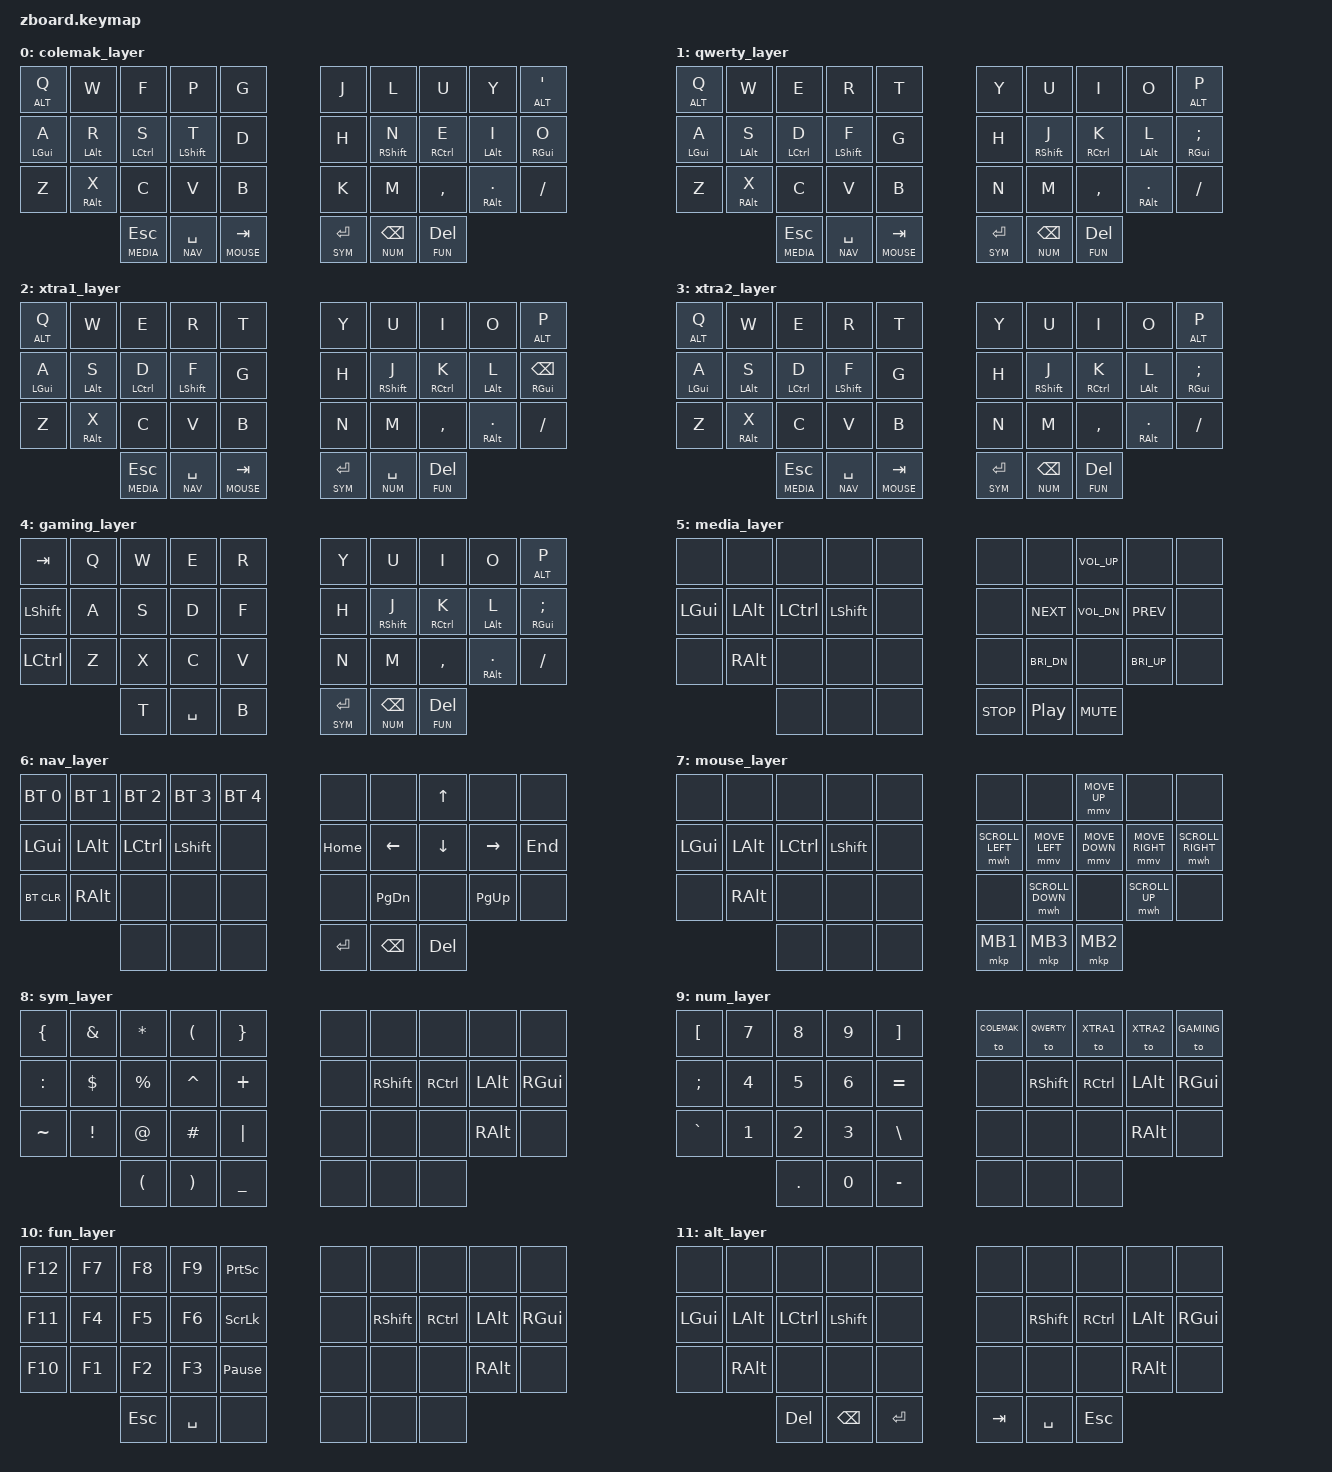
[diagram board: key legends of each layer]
/*
 * Copyright (c) 2020 The ZMK Contributors
 *
 * SPDX-License-Identifier: MIT
 */

#include <behaviors.dtsi>
#include <dt-bindings/zmk/keys.h>
#include <dt-bindings/zmk/bt.h>
#include <dt-bindings/zmk/mouse.h>


&mt {
   flavor = "tap-preferred";
   tapping_term_ms = <200>;
};

&caps_word {
    continue-list = <UNDERSCORE MINUS BACKSPACE>;
};

&mmv {
  time-to-max-speed-ms = <1000>;
  acceleration-exponent = <1>;
};

&mwh {
  time-to-max-speed-ms = <3000>;
  acceleration-exponent = <1>;
};

#define U_MOUSE_MOVE_MAX 1000
#define U_MOUSE_SCROLL_MAX 100

#undef MOVE_UP
#undef MOVE_DOWN
#undef MOVE_LEFT
#undef MOVE_RIGHT
#define MOVE_UP MOVE_VERT(-U_MOUSE_MOVE_MAX)
#define MOVE_DOWN MOVE_VERT(U_MOUSE_MOVE_MAX)
#define MOVE_LEFT MOVE_HOR(-U_MOUSE_MOVE_MAX)
#define MOVE_RIGHT MOVE_HOR(U_MOUSE_MOVE_MAX)

#undef SCROLL_UP
#undef SCROLL_DOWN
#undef SCROLL_LEFT
#undef SCROLL_RIGHT
#define SCROLL_UP SCROLL_VERT(U_MOUSE_SCROLL_MAX)
#define SCROLL_DOWN SCROLL_VERT(-U_MOUSE_SCROLL_MAX)
#define SCROLL_LEFT SCROLL_HOR(-U_MOUSE_SCROLL_MAX)
#define SCROLL_RIGHT SCROLL_HOR(U_MOUSE_SCROLL_MAX)

/ { 
#define COLEMAK 0
#define QWERTY 1
#define XTRA1 2
#define XTRA2 3
#define GAMING 4
#define MEDIA 5
#define NAV 6
#define MOUSE 7
#define SYM 8
#define NUM 9
#define FUN 10
#define ALT 11


combos {
    compatible = "zmk,combos";
    
    combo_caps {
        layers = <0>;
        timeout-ms = <70>;
        key-positions = <13 16>;
        bindings = <&caps_word>;
    };
    

    
};


        keymap {
                compatible = "zmk,keymap";
                
       		colemak_layer {
		bindings = <
		&lt ALT Q      &kp W       &kp F          &kp P          &kp G              &kp J         &kp L         &kp U         &kp Y        &lt ALT SQT 
		&mt LGUI A &mt LALT R  &mt LCTRL S    &mt LSHFT T    &kp D              &kp H         &mt RSHFT N   &mt RCTRL E   &mt LALT I   &mt RGUI O
		&kp Z      &mt RALT X  &kp C          &kp V          &kp B              &kp K         &kp M         &kp COMMA     &mt RALT DOT &kp FSLH
          				       &lt MEDIA ESC &lt NAV SPACE &lt MOUSE TAB        &lt SYM ENTER &lt NUM BSPC  &lt FUN DEL
		>;
		};
		
		qwerty_layer {
		bindings = <
		&lt ALT Q      &kp W       &kp E          &kp R          &kp T           &kp Y         &kp U         &kp I         &kp O        &lt ALT P 
		&mt LGUI A  &mt LALT S  &mt LCTRL D    &mt LSHFT F    &kp G              &kp H         &mt RSHFT J   &mt RCTRL K   &mt LALT L  &mt RGUI SEMI
		&kp Z      &mt RALT X  &kp C          &kp V          &kp B              &kp N         &kp M         &kp COMMA     &mt RALT DOT &kp FSLH
          				       &lt MEDIA ESC &lt NAV SPACE &lt MOUSE TAB        &lt SYM ENTER &lt NUM BSPC  &lt FUN DEL
		>;
		};
		
		xtra1_layer {
		bindings = <
		&lt ALT Q      &kp W       &kp E          &kp R          &kp T              &kp Y         &kp U         &kp I         &kp O        &lt ALT P 
		&mt LGUI A  &mt LALT S  &mt LCTRL D    &mt LSHFT F    &kp G              &kp H         &mt RSHFT J   &mt RCTRL K   &mt LALT L  &mt RGUI BSPC
		&kp Z      &mt RALT X  &kp C          &kp V          &kp B              &kp N         &kp M         &kp COMMA     &mt RALT DOT &kp FSLH
          				       &lt MEDIA ESC &lt NAV SPACE &lt MOUSE TAB        &lt SYM ENTER &lt NUM SPACE  &lt FUN DEL
		>;
		};
		
		xtra2_layer {
		bindings = <
		&lt ALT Q      &kp W       &kp E          &kp R          &kp T              &kp Y         &kp U         &kp I         &kp O        &lt ALT P 
		&mt LGUI A  &mt LALT S  &mt LCTRL D    &mt LSHFT F    &kp G              &kp H         &mt RSHFT J   &mt RCTRL K   &mt LALT L  &mt RGUI SEMI
		&kp Z      &mt RALT X  &kp C          &kp V          &kp B              &kp N         &kp M         &kp COMMA     &mt RALT DOT &kp FSLH
          				       &lt MEDIA ESC &lt NAV SPACE &lt MOUSE TAB        &lt SYM ENTER &lt NUM BSPC  &lt FUN DEL
		>;
		};
		
		gaming_layer {
		bindings = <
		&kp TAB     &kp Q   &kp W    &kp E   &kp R              &kp Y         &kp U         &kp I         &kp O        &lt ALT P 
		&kp LSHIFT  &kp A   &kp S    &kp D   &kp F              &kp H         &mt RSHFT J   &mt RCTRL K   &mt LALT L  &mt RGUI SEMI
		&kp LCTRL   &kp Z   &kp X    &kp C   &kp V              &kp N         &kp M         &kp COMMA     &mt RALT DOT &kp FSLH
          	                     &kp T &kp SPACE &kp B        &lt SYM ENTER &lt NUM BSPC  &lt FUN DEL
		>;
		};
		
		

       		media_layer {
                        bindings = <
   		&none      &none       &none          &none          &none              &none         &none        &kp C_VOL_UP  &none        &none 
   		&kp LGUI   &kp LALT    &kp LCTRL      &kp LSHFT      &none              &none         &kp C_NEXT   &kp C_VOL_DN  &kp C_PREV   &none
   		&none      &kp RALT    &none          &none          &none              &none         &kp C_BRI_DN &none         &kp C_BRI_UP &none
                         		&none	      &none          &none              &kp C_STOP    &kp C_PP     &kp C_MUTE  
                        >;
                };

                nav_layer {
                        bindings = <
   		&bt BT_SEL 0 &bt BT_SEL 1 &bt BT_SEL 2   &bt BT_SEL 3   &bt BT_SEL 4       &none         &none        &kp UP        &none        &none   
   		&kp LGUI     &kp LALT     &kp LCTRL      &kp LSHFT      &none              &kp HOME      &kp LEFT     &kp DOWN      &kp RIGHT    &kp END
   		&bt BT_CLR   &kp RALT     &none          &none          &none              &none         &kp PG_DN    &none         &kp PG_UP    &none  
                                    &none        &none          &none              &kp ENTER     &kp BSPC     &kp DEL      
                        >;
                };

                mouse_layer {
                        bindings = <
   		&none      &none       &none          &none          &none              &none         &none        &mmv MOVE_UP        &none        &none  
   		&kp LGUI   &kp LALT    &kp LCTRL      &kp LSHFT      &none              &mwh SCROLL_LEFT  &mmv MOVE_LEFT     &mmv MOVE_DOWN      &mmv MOVE_RIGHT    &mwh SCROLL_RIGHT
   		&none      &kp RALT    &none          &none          &none              &none         &mwh SCROLL_DOWN   &none         &mwh SCROLL_UP    &none  
                          	   &none          &none          &none              &mkp MB1     &mkp MB3    &mkp MB2    
                        >;
                };

                sym_layer {
                        bindings = <
        &kp LBRC   &kp AMPS    &kp STAR       &kp LPAR       &kp RBRC           &none         &none        &none         &none        &none   
        &kp COLON  &kp DLLR    &kp PRCNT      &kp CARET      &kp PLUS           &none         &kp RSHFT    &kp RCTRL     &kp LALT     &kp RGUI
        &kp TILDE  &kp EXCL    &kp AT         &kp HASH       &kp PIPE           &none         &none        &none         &kp RALT     &none   
                               	    &kp LPAR  &kp RPAR       &kp UNDER          &none         &none        &none
                        >;
                };

                num_layer {
                        bindings = <
         &kp LBKT   &kp N7      &kp N8         &kp N9         &kp RBKT           &to COLEMAK   &to QWERTY   &to XTRA1     &to XTRA2   &to GAMING  
         &kp SEMI   &kp N4      &kp N5         &kp N6         &kp EQUAL          &none         &kp RSHFT    &kp RCTRL     &kp LALT     &kp RGUI
         &kp GRAVE  &kp N1      &kp N2         &kp N3         &kp BSLH           &none         &none        &none         &kp RALT     &none   
                               	       &kp DOT        &kp N0  &kp MINUS            &none &none         &none
                        >;
                };

                fun_layer {
                        bindings = <
  	 	 &kp F12    &kp F7      &kp F8         &kp F9         &kp PSCRN        		&none         &none        &none         &none        &none    
         &kp F11    &kp F4      &kp F5         &kp F6         &kp SLCK           &none         &kp RSHFT    &kp RCTRL     &kp LALT     &kp RGUI
         &kp F10    &kp F1      &kp F2         &kp F3         &kp PAUSE_BREAK    &none         &none        &none         &kp RALT     &none   
                                			   &kp ESC        &kp SPACE  &none    &none        &none        &none
                        >;
                };
		
		alt_layer {
                        bindings = <
        &none      &none       &none          &none          &none           &none         &none        &none         &none        &none   
        &kp LGUI   &kp LALT    &kp LCTRL      &kp LSHFT      &none           &none         &kp RSHFT    &kp RCTRL     &kp LALT     &kp RGUI
        &none      &kp RALT    &none          &none          &none           &none         &none        &none         &kp RALT     &none   
                               	           &kp DEL &kp BSPC &kp ENTER        &kp TAB &kp SPACE &kp ESC               
                        >;
                };
		

        
	};
};
